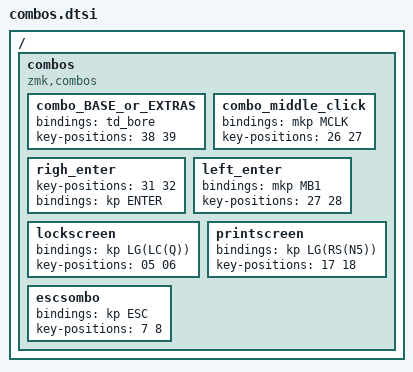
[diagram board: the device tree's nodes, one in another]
/ {
    combos {
        compatible = "zmk,combos";

        combo_BASE_or_EXTRAS {
            bindings = <&td_bore>;
            key-positions = <38 39>;
        };
        
        combo_middle_click {
            bindings = <&mkp MCLK>;
            key-positions = <26 27>;
        };
                
        righ_enter {
            key-positions = <31 32>;
            bindings = <&kp ENTER>;
        };

        left_enter {
            bindings = <&mkp MB1>;
            key-positions = <27 28>;
        };

        lockscreen {
            bindings = <&kp LG(LC(Q))>;
            key-positions = <05 06>;
        };

        printscreen {
            bindings = <&kp LG(RS(N5))>;
            key-positions = <17 18>;
        };
        escsombo {
            bindings = <&kp ESC>;
            key-positions = <7 8>;
        };
    };
};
